# AltaRiscv register map
File version: 1.0
Registers are 32-bit, read-write, reset 0x0 unless marked. A register's access mark holds for its fields unless they carry their own. Offsets are from the block's base; [hi:lo] are bit positions; {n}, {i} and the like mark numbered series.

## FLASH — Flash controller
Base 0x40001000
0x04 FLASH_KEYR — Flash key register
0x08 FLASH_OPTKEYR — Flash OPTKEY register
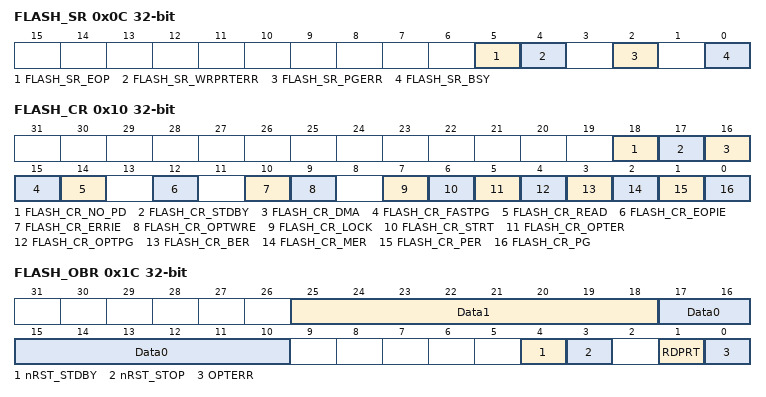
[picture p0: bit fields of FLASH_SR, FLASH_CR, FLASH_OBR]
0x0C FLASH_SR access per field — Flash status register
  [5] FLASH_SR_EOP rw — End of operation
  [4] FLASH_SR_WRPRTERR rw — Write protection error
  [2] FLASH_SR_PGERR rw — Programming error
  [0] FLASH_SR_BSY ro — Flash busy
0x10 FLASH_CR — Flash control register
  [18] FLASH_CR_NO_PD — Flash no power down
  [17] FLASH_CR_STDBY — Flash standby, which disables fast read
  [16] FLASH_CR_DMA — Flash DMA programming
  [15] FLASH_CR_FASTPG — Flash fast programming
  [14] FLASH_CR_READ — Flash flexible read
  [12] FLASH_CR_EOPIE — End of operation interrupt enable
  [10] FLASH_CR_ERRIE — Error interrupt enable
  [9] FLASH_CR_OPTWRE — Option bytes write enable
  [7] FLASH_CR_LOCK — Flash lock
  [6] FLASH_CR_STRT — Flash erase start
  [5] FLASH_CR_OPTER — Option byte erase
  [4] FLASH_CR_OPTPG — Option byte programming
  [3] FLASH_CR_BER — Flash block erase
  [2] FLASH_CR_MER — Flash mass erase
  [1] FLASH_CR_PER — Flash page erase
  [0] FLASH_CR_PG — Flash programming
0x14 FLASH_AR — Flash address register
0x1C FLASH_OBR ro — Option byte register
  [25:18] Data1
  [17:10] Data0
  [4] nRST_STDBY — Generate reset when entering standby mode
  [3] nRST_STOP — Generate reset when entering stop mode
  [1] RDPRT — Read protection
  [0] OPTERR — Option byte load error
0x20 FLASH_WRPR ro — Write protection register
0x24 FLASH_CONFIG ro — Flash configuratioin
0x28 FLASH_DMA_DATA wo
0x2C FLASH_READ_CTRL
0x30 FLASH_READ_DATA ro

## FCB0 — FCB registers
Base 0x40010000
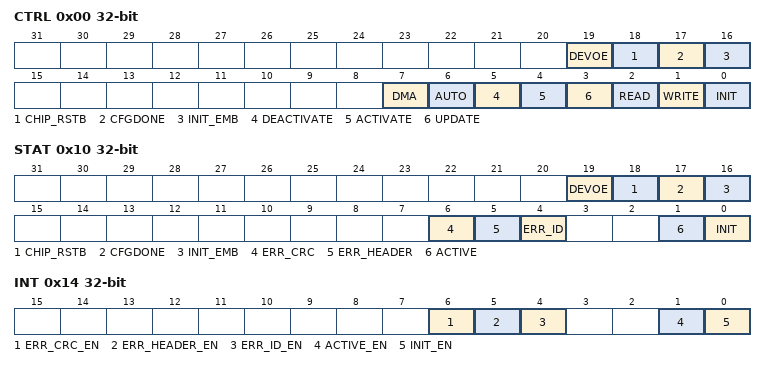
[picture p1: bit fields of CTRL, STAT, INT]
0x00 CTRL — Control register
  [19] DEVOE
  [18] CHIP_RSTB
  [17] CFGDONE
  [16] INIT_EMB
  [7] DMA — Use FCB is tshe dma flow controller
  [6] AUTO — Reset auto configuration mode
  [5] DEACTIVATE — De-activate the FPGA configuration
  [4] ACTIVATE — Activate the FPGA configuration
  [3] UPDATE — Update current chain
  [2] READ — Read operation
  [1] WRITE — Write operation
  [0] INIT — Initialize sram
0x04 ADDR — Address register
0x08 DATA
0x0C AUTO — Auto configuration register
0x10 STAT ro — Status register
  [19] DEVOE
  [18] CHIP_RSTB
  [17] CFGDONE
  [16] INIT_EMB
  [6] ERR_CRC — CRC error
  [5] ERR_HEADER — Header error
  [4] ERR_ID — ID error
  [1] ACTIVE — FPGA active
  [0] INIT — Sram initialization
0x14 INT — Interrupt register
  [6] ERR_CRC_EN — CRC error interrupt enable
  [5] ERR_HEADER_EN — Header error interrupt enable
  [4] ERR_ID_EN — ID error interrupt enable
  [1] ACTIVE_EN — FPGA active interrupt enable
  [0] INIT_EN — Sram initialization interrupt enable

## WATCHDOG0 — WATCHDOG registers
Base 0x40011000
0x00 WdogLoad — Load Register
0x04 WdogValue ro — Value Register
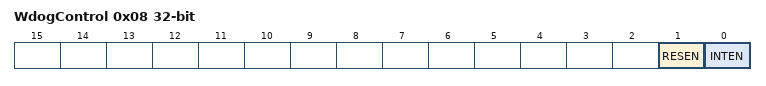
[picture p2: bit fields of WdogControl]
0x08 WdogControl — Control register
  [1] RESEN — Reset enable
  [0] INTEN — Interrupt enable
0x0C WdogIntClr wo — Interrupt Clear Register
  [0] WdogIntClr
0x10 WdogRIS ro — Raw Interrupt Status Register
  [0] WdogRIS
0x14 WdogMIS ro — Masked Interrupt Status Register
  [0] WdogMIS
0xC00 WdogLock — Lock Register

## SPI0 — SPI registers
Base 0x40012000
Same registers: SPI1 0x40013000
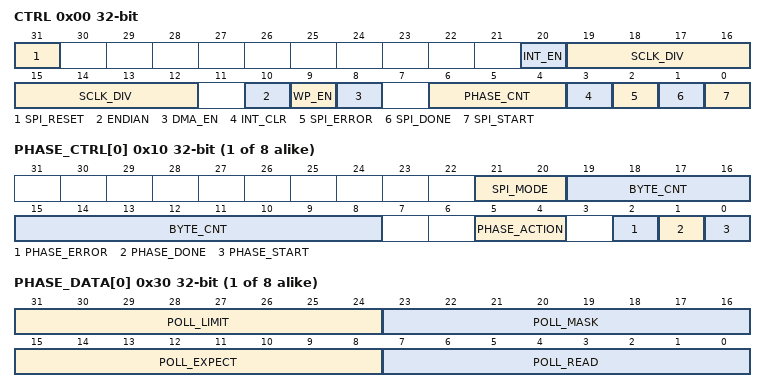
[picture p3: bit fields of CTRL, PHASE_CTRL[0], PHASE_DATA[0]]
0x00 CTRL — Control register
  [31] SPI_RESET
  [20] INT_EN — Interrupt enable
  [19:12] SCLK_DIV — Sclk divider
    2=Div 2; 4=Div 4; 8=Div 8; 16=Div 16; 32=Div 32; 64=Div 64; 128=Div 128; 0=Div 256
  [10] ENDIAN — Endian select
    0=BE; 1=LE
  [9] WP_EN — WP enable
  [8] DMA_EN — DMA enable for last phase
  [6:4] PHASE_CNT — Phase count
  [3] INT_CLR — Interrupt clear
  [2] SPI_ERROR — SPI operation error
  [1] SPI_DONE — SPI operation done
  [0] SPI_START — SPI start operation
{0x10+4i} PHASE_CTRL[{i}] access per field (i=0..7) — Phase control {i}
  [21:20] SPI_MODE rw
    0=Single; 1=Dual; 2=Quad
  [19:8] BYTE_CNT rw — Phase byte count
  [5:4] PHASE_ACTION rw
    0=TX; 1=Dummy TX; 2=RX; 3=Poll
  [2] PHASE_ERROR ro
  [1] PHASE_DONE ro
  [0] PHASE_START ro
{0x30+4i} PHASE_DATA[{i}] (i=0..7)
  [31:24] POLL_LIMIT
  [23:16] POLL_MASK
  [15:8] POLL_EXPECT — Poll expected value
  [7:0] POLL_READ — Poll read value
